# STM32F3x4 register map
File version: 1.8
CPU: CM4 r1p0, little endian, MPU, FPU, 4 interrupt priority bits
Registers are 32-bit, read-write, reset 0x0 unless marked. A register's access mark holds for its fields unless they carry their own. Offsets are from the block's base; [hi:lo] are bit positions; 'fields as' and 'values as' point back to an identical list.

## COMP — General purpose comparators
Base 0x40010000
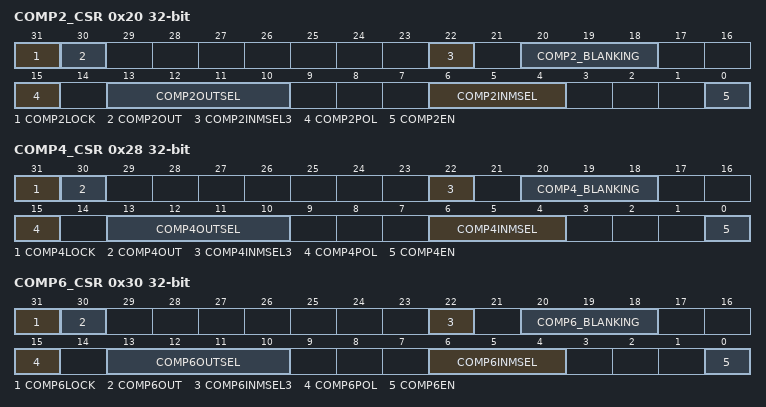
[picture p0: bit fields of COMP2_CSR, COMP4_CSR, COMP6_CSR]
0x20 COMP2_CSR access per field — control and status register
  [31] COMP2LOCK rw — Comparator 2 lock
    0=Unlocked (Comparator CSR bits are read-write); 1=Locked (Comparator CSR bits are read-only)
  [30] COMP2OUT ro — Comparator 2 output
    0=Low (Non-inverting input below inverting input); 1=High (Non-inverting input above inverting input)
  [22] COMP2INMSEL3 rw — Comparator 2 inverting input selection
  [20:18] COMP2_BLANKING rw — Comparator 2 blanking source
    0=NoBlanking; 1=TIM1OC5 (TIM1 OC5 selected as blanking source); 2=TIM2OC3 (TIM2 OC3 selected as blanking source); 3=TIM3OC3 (TIM3 OC3 selected as blanking source)
  [15] COMP2POL rw — Comparator 2 output polarity
    0=NotInverted (Output is not inverted); 1=Inverted (Output is inverted)
  [13:10] COMP2OUTSEL rw — Comparator 2 output selection
    0=NoSelection; 1=Timer1BreakInput; 2=Timer1BreakInput2; 6=Timer1OCRefClearInput (Timer 1 OCREF_CLR input); 7=Timer1InputCapture1; 8=Timer2InputCapture4; 9=Timer2OCRefClearInput (Timer 2 OCREF_CLR input); 10=Timer3InputCapture1; 11=Timer3OCRefClearInput (Timer 3 OCREF_CLR input)
  [6:4] COMP2INMSEL rw — Comparator 2 inverting input selection
    0=OneQuarterVRef (1/4 of VRefint); 1=OneHalfVRef (1/2 of VRefint); 2=ThreeQuarterVRef (3/4 of VRefint); 3=VRefint; 4=PA4_DAC1_CH1 (PA4 or DAC1_CH1 output if enabled); 5=DAC1_CH2; 6=PA2
  [0] COMP2EN rw — Comparator 2 enable
    0=Disabled (Comparator disabled); 1=Enabled (Comparator enabled)
0x28 COMP4_CSR access per field — control and status register
  [31] COMP4LOCK rw — Comparator 4 lock
    values as COMP2_CSR.COMP2LOCK
  [30] COMP4OUT ro — Comparator 4 output
    values as COMP2_CSR.COMP2OUT
  [22] COMP4INMSEL3 rw — Comparator 4 inverting input selection
  [20:18] COMP4_BLANKING rw — Comparator 4 blanking source
    0=NoBlanking; 1=TIM3OC4 (TIM3 OC4 selected as blanking source); 3=TIM15OC1 (TIM15 OC1 selected as blanking source)
  [15] COMP4POL rw — Comparator 4 output polarity
    values as COMP2_CSR.COMP2POL
  [13:10] COMP4OUTSEL rw — Comparator 4 output selection
    0=NoSelection; 1=Timer1BreakInput; 2=Timer1BreakInput2; 6=Timer3InputCapture3; 8=Timer15InputCapture2; 10=Timer15OCRefClearInput (Timer 15 OCREF_CLR input); 11=Timer3OCRefClearInput (Timer 3 OCREF_CLR input)
  [6:4] COMP4INMSEL rw — Comparator 4 inverting input selection
    0=OneQuarterVRef (1/4 of VRefint); 1=OneHalfVRef (1/2 of VRefint); 2=ThreeQuarterVRef (3/4 of VRefint); 3=VRefint; 4=PA4_DAC1_CH1 (PA4 or DAC1_CH1 output if enabled); 5=DAC1_CH2; 7=PB2
  [0] COMP4EN rw — Comparator 4 enable
    values as COMP2_CSR.COMP2EN
0x30 COMP6_CSR access per field — control and status register
  [31] COMP6LOCK rw — Comparator 6 lock
    values as COMP2_CSR.COMP2LOCK
  [30] COMP6OUT ro — Comparator 6 output
    values as COMP2_CSR.COMP2OUT
  [22] COMP6INMSEL3 rw — Comparator 6 inverting input selection
  [20:18] COMP6_BLANKING rw — Comparator 6 blanking source
    0=NoBlanking; 3=TIM2OC4 (TIM2 OC4 selected as blanking source); 4=TIM15OC2 (TIM15 OC2 selected as blanking source)
  [15] COMP6POL rw — Comparator 6 output polarity
    values as COMP2_CSR.COMP2POL
  [13:10] COMP6OUTSEL rw — Comparator 6 output selection
    0=NoSelection; 1=Timer1BreakInput; 2=Timer1BreakInput2; 6=Timer2InputCapture2; 8=Timer2OCRefClearInput (Timer 2 OCREF_CLR input); 9=Timer16OCRefClearInput (Timer 16 OCREF_CLR input); 10=Timer16InputCapture1
  [6:4] COMP6INMSEL rw — Comparator 6 inverting input selection
    0=OneQuarterVRef (1/4 of VRefint); 1=OneHalfVRef (1/2 of VRefint); 2=ThreeQuarterVRef (3/4 of VRefint); 3=VRefint; 4=PA4_DAC1_CH1 (PA4 or DAC1_CH1 output if enabled); 5=DAC1_CH2; 7=PB15
  [0] COMP6EN rw — Comparator 6 enable
    values as COMP2_CSR.COMP2EN
